# SA3_SS_PKTDMA_0_PKTDMA_GCFG_44910000h register map
Vendor: Texas Instruments
Peripheral module from a debugger description file (folder AM275x).
Registers are 32-bit, read-write, reset 0x0 unless marked. A register's access mark holds for its fields unless they carry their own. Offsets are as the file gives them; lines under a group give offsets from that group; [hi:lo] are bit positions; {n}, {i} and the like mark numbered series; 'fields as' and 'values as' point back to an identical list; <NAME> marks a mode.

## pktdma_gcfg
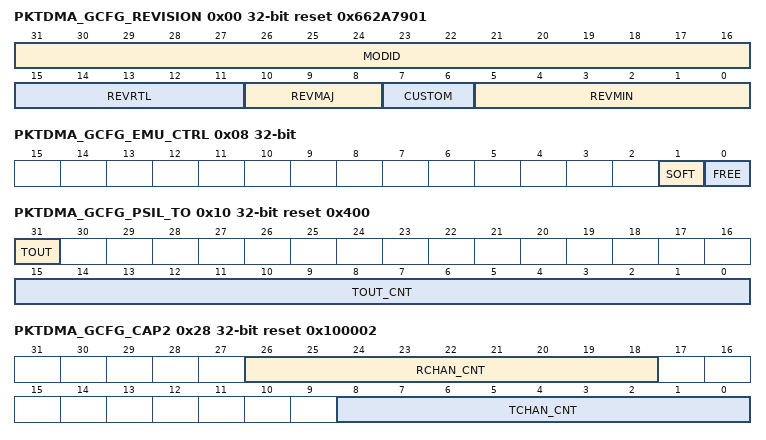
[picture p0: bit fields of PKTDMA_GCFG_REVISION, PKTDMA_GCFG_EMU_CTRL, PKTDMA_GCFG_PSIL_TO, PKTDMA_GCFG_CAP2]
0x00 PKTDMA_GCFG_REVISION ro reset 0x662A7901 — The Revision Register contains the major and minor revisions for the module.
  [31:16] MODID — Module ID field Reset Source: rst_mod_g_rst_n
  [15:11] REVRTL — RTL revision. Will vary depending on release. Reset Source: rst_mod_g_rst_n
  [10:8] REVMAJ — Major revision Reset Source: rst_mod_g_rst_n
  [7:6] CUSTOM — Custom Reset Source: rst_mod_g_rst_n
  [5:0] REVMIN — Minor revision Reset Source: rst_mod_g_rst_n
0x04 PKTDMA_GCFG_PERF_CTRL reset 0x40 — The performance control register contains fields which can be used to adjust the performance of the PKTDMA in the system.
  [15:0] TIMEOUT_CNT — This feature is not currently supported Reset Source: rst_mod_g_rst_n
0x08 PKTDMA_GCFG_EMU_CTRL — The emulation control register is used to control the behavior of the DMA when the emususp input is asserted.
  [1] SOFT — Soft Reset Source: rst_mod_g_rst_n
  [0] FREE — Free Reset Source: rst_mod_g_rst_n
0x10 PKTDMA_GCFG_PSIL_TO reset 0x400 — The PSI-L proxy timeout register controls the timeout watchdog and reports timeout occurrances on PSI-L configuration transactions issued by the built in PSI-L proxy.
  [31] TOUT — Timeout occurred. When set indicates that a timeout has occurred on a config access Reset Source: rst_mod_g_rst_n
  [15:0] TOUT_CNT — Timeout period. Specifies how many cycles to wait before closing up a conifiguration read or write transaction and asserting the tout bit Reset Source: rst_mod_g_rst_n
0x20 PKTDMA_GCFG_CAP0 access not given reset not defined — The Capabilities Register 0 specifies which standard features this PKTDMA instance supports.
0x24 PKTDMA_GCFG_CAP1 access not given reset not defined — The Capabilities Register 1 specifies which standard features this PKTDMA instance supports.
0x28 PKTDMA_GCFG_CAP2 ro reset 0x100002 — The Capabilities Register 2 specifies how many resources this PKTDMA instance supports.
  [26:18] RCHAN_CNT — Rx internal channel count Reset Source: rst_mod_g_rst_n
  [8:0] TCHAN_CNT — Tx internal channel count Reset Source: rst_mod_g_rst_n
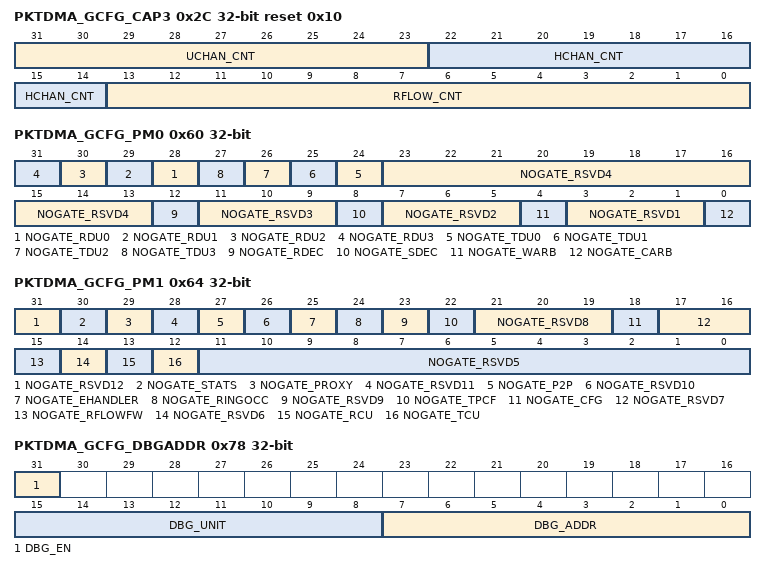
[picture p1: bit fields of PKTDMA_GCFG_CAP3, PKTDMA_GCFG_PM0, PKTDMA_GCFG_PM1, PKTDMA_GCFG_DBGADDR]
0x2C PKTDMA_GCFG_CAP3 ro reset 0x10 — The Capabilities Register 3 specifies how many resources this PKTDMA instance supports.
  [31:23] UCHAN_CNT — Tx ultra high capacity internal channel count Reset Source: rst_mod_g_rst_n
  [22:14] HCHAN_CNT — Tx high capacity internal channel count Reset Source: rst_mod_g_rst_n
  [13:0] RFLOW_CNT — Rx flow table entry count Reset Source: rst_mod_g_rst_n
0x30 PKTDMA_GCFG_CAP4 ro reset 0x10 — The Capabilities Register 4 specifies how many resources this PKTDMA instance supports.
  [13:0] TFLOW_CNT — Tx flow table entry count Reset Source: rst_mod_g_rst_n
0x60 PKTDMA_GCFG_PM0 — This register enables or inhibits automatic clock gating to individual sub-blocks
  [n+28] NOGATE_RDU{n} (n=0..3) — When set inhibits automatic gating of clock. Reset Source: rst_mod_g_rst_n
  [n+24] NOGATE_TDU{n} (n=0..3) — When set inhibits automatic gating of clock. Reset Source: rst_mod_g_rst_n
  [23:13] NOGATE_RSVD4 — Reserved PM signals. Reset Source: rst_mod_g_rst_n
  [12] NOGATE_RDEC — When set inhibits automatic gating of clock. Reset Source: rst_mod_g_rst_n
  [11:9] NOGATE_RSVD3 — Reserved PM signals. Reset Source: rst_mod_g_rst_n
  [8] NOGATE_SDEC — When set inhibits automatic gating of clock. Reset Source: rst_mod_g_rst_n
  [7:5] NOGATE_RSVD2 — Reserved PM signals. Reset Source: rst_mod_g_rst_n
  [4] NOGATE_WARB — When set inhibits automatic gating of clock. Reset Source: rst_mod_g_rst_n
  [3:1] NOGATE_RSVD1 — Reserved PM signals. Reset Source: rst_mod_g_rst_n
  [0] NOGATE_CARB — When set inhibits automatic gating of clock. Reset Source: rst_mod_g_rst_n
0x64 PKTDMA_GCFG_PM1 — This register enables or inhibits automatic clock gating to individual sub-blocks
  [31] NOGATE_RSVD12 — Reserved PM signals. Reset Source: rst_mod_g_rst_n
  [30] NOGATE_STATS — When set inhibits automatic gating of clock. Reset Source: rst_mod_g_rst_n
  [29] NOGATE_PROXY — When set inhibits automatic gating of clock. Reset Source: rst_mod_g_rst_n
  [28] NOGATE_RSVD11 — Reserved PM signals. Reset Source: rst_mod_g_rst_n
  [27] NOGATE_P2P — When set inhibits automatic gating of clock. Reset Source: rst_mod_g_rst_n
  [26] NOGATE_RSVD10 — Reserved PM signals. Reset Source: rst_mod_g_rst_n
  [25] NOGATE_EHANDLER — When set inhibits automatic gating of clock. Reset Source: rst_mod_g_rst_n
  [24] NOGATE_RINGOCC — When set inhibits automatic gating of clock. Reset Source: rst_mod_g_rst_n
  [23] NOGATE_RSVD9 — Reserved PM signals. Reset Source: rst_mod_g_rst_n
  [22] NOGATE_TPCF — When set inhibits automatic gating of clock. Reset Source: rst_mod_g_rst_n
  [21:19] NOGATE_RSVD8 — Reserved PM signals. Reset Source: rst_mod_g_rst_n
  [18] NOGATE_CFG — When set inhibits automatic gating of clock. Reset Source: rst_mod_g_rst_n
  [17:16] NOGATE_RSVD7 — Reserved PM signals. Reset Source: rst_mod_g_rst_n
  [15] NOGATE_RFLOWFW — When set inhibits automatic gating of clock. Reset Source: rst_mod_g_rst_n
  [14] NOGATE_RSVD6 — Reserved PM signals. Reset Source: rst_mod_g_rst_n
  [13] NOGATE_RCU — When set inhibits automatic gating of clock. Reset Source: rst_mod_g_rst_n
  [12] NOGATE_TCU — When set inhibits automatic gating of clock. Reset Source: rst_mod_g_rst_n
  [11:0] NOGATE_RSVD5 — Reserved PM signals. Reset Source: rst_mod_g_rst_n
0x78 PKTDMA_GCFG_DBGADDR — This register provides a writable address which allows debug information to be read from the Debug Data Register
  [31] DBG_EN — Debug enable Reset Source: rst_mod_g_rst_n
  [15:8] DBG_UNIT — Selects which unit to read debug information from Reset Source: rst_mod_g_rst_n
  [7:0] DBG_ADDR — Selects offset within unit to access seperate debug registers Reset Source: rst_mod_g_rst_n
0x7C PKTDMA_GCFG_DBGDATA ro — This register provides read only debug data
  [31:0] DBG_DATA — Provides debug information from various internal units. The value which is read back depends on which unit and register are selected in the Debug Address Register Reset Source: rst_mod_g_rst_n
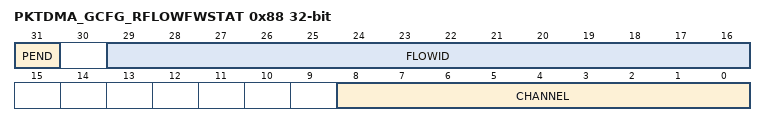
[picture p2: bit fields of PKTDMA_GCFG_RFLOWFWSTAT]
0x88 PKTDMA_GCFG_RFLOWFWSTAT — The Rx Flow FW Status Register 0 captures information about the thread/channel and received flow ID which failed a range check. Values in this register will remain persistent once an exception has been detected until the pend bit is written back to 0
  [31] PEND — This bit is set whenever the Flow ID firewall detects a Flow ID is out of range for an incoming packet. Once this bit is set, the remaining fields in this register will not be modified. SW is required to write this bit to 0 to allow another exception to be captured. Reset Source: rst_mod_g_rst_n
  [29:16] FLOWID — This is the flow ID that was received on the trapped packet Reset Source: rst_mod_g_rst_n
  [8:0] CHANNEL — This is the channel number on which the trapped packet was received Reset Source: rst_mod_g_rst_n
